# HC32F155 register map
File version: 1.0
CPU: CM0+ r0p1, little endian, no MPU, no FPU, 2 interrupt priority bits
Registers are 32-bit, read-write, reset 0x0 unless marked. A register's access mark holds for its fields unless they carry their own. Offsets are from the block's base; [hi:lo] are bit positions; {n}, {i} and the like mark numbered series.

## I2C
Base 0x40004800
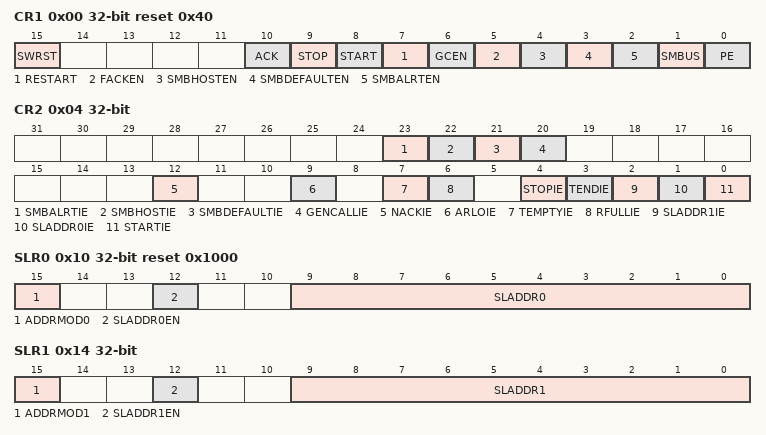
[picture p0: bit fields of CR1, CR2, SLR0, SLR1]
0x00 CR1 reset 0x40
  [15] SWRST, [10] ACK, [9] STOP, [8] START, [7] RESTART, [6] GCEN, [5] FACKEN, [4] SMBHOSTEN, [3] SMBDEFAULTEN, [2] SMBALRTEN, [1] SMBUS, [0] PE
0x04 CR2
  [23] SMBALRTIE, [22] SMBHOSTIE, [21] SMBDEFAULTIE, [20] GENCALLIE, [12] NACKIE, [9] ARLOIE, [7] TEMPTYIE, [6] RFULLIE, [4] STOPIE, [3] TENDIE, [2] SLADDR1IE, [1] SLADDR0IE, [0] STARTIE
0x0C CR4 reset 0x300307
  [10] BUSWAIT
0x10 SLR0 reset 0x1000
  [15] ADDRMOD0, [12] SLADDR0EN, [9:0] SLADDR0
0x14 SLR1
  [15] ADDRMOD1, [12] SLADDR1EN, [9:0] SLADDR1
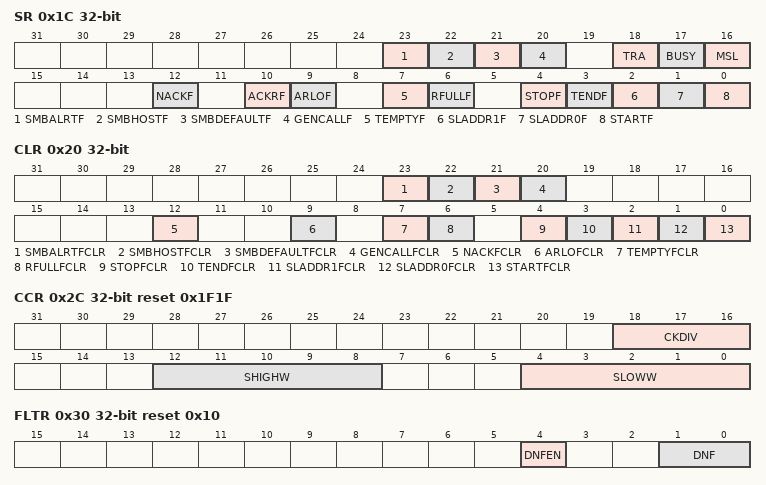
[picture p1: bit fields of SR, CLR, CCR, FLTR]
0x1C SR
  [23] SMBALRTF ro, [22] SMBHOSTF ro, [21] SMBDEFAULTF ro, [20] GENCALLF ro, [18] TRA, [17] BUSY ro, [16] MSL, [12] NACKF ro, [10] ACKRF ro, [9] ARLOF ro, [7] TEMPTYF ro, [6] RFULLF ro, [4] STOPF ro, [3] TENDF ro, [2] SLADDR1F ro, [1] SLADDR0F ro, [0] STARTF ro
0x20 CLR wo
  [23] SMBALRTFCLR, [22] SMBHOSTFCLR, [21] SMBDEFAULTFCLR, [20] GENCALLFCLR, [12] NACKFCLR, [9] ARLOFCLR, [7] TEMPTYFCLR, [6] RFULLFCLR, [4] STOPFCLR, [3] TENDFCLR, [2] SLADDR1FCLR, [1] SLADDR0FCLR, [0] STARTFCLR
0x24 DTR 8-bit reset 0xFF
0x28 DRR 8-bit
0x2C CCR reset 0x1F1F
  [18:16] CKDIV, [12:8] SHIGHW, [4:0] SLOWW
0x30 FLTR reset 0x10
  [4] DNFEN, [1:0] DNF

## ICG
Base 0x000000C0
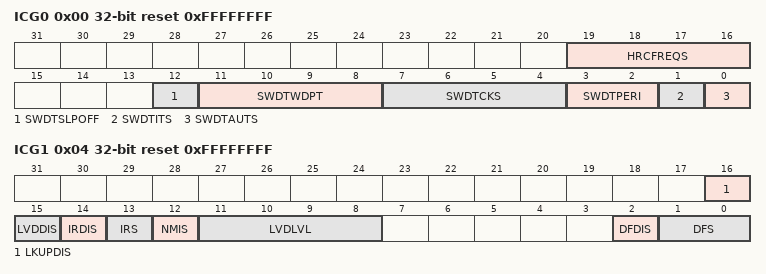
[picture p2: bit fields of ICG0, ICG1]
0x00 ICG0 ro reset 0xFFFFFFFF
  [19:16] HRCFREQS, [12] SWDTSLPOFF, [11:8] SWDTWDPT, [7:4] SWDTCKS, [3:2] SWDTPERI, [1] SWDTITS, [0] SWDTAUTS
0x04 ICG1 ro reset 0xFFFFFFFF
  [16] LKUPDIS, [15] LVDDIS, [14] IRDIS, [13] IRS, [12] NMIS, [11:8] LVDLVL, [2] DFDIS, [1:0] DFS
{0x0+4i} ICG{i} ro reset 0xFFFFFFFF (reset mask 0x0) (i=2..6)

## INTC
Base 0x40011000
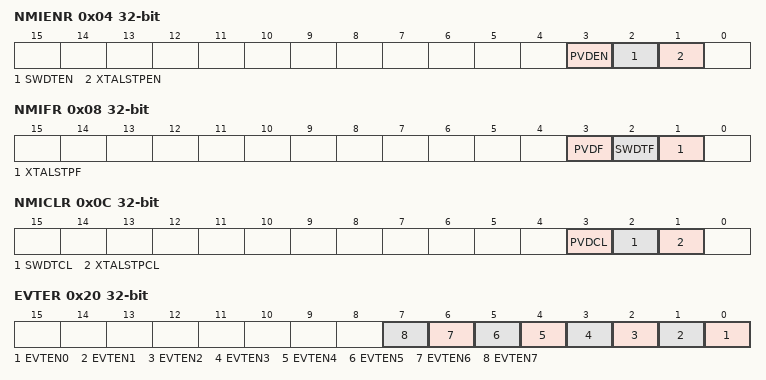
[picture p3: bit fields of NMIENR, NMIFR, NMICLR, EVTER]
0x04 NMIENR
  [3] PVDEN, [2] SWDTEN, [1] XTALSTPEN
0x08 NMIFR ro
  [3] PVDF, [2] SWDTF, [1] XTALSTPF
0x0C NMICLR
  [3] PVDCL, [2] SWDTCL, [1] XTALSTPCL
0x20 EVTER
  [n] EVTEN{n} (n=0..7)
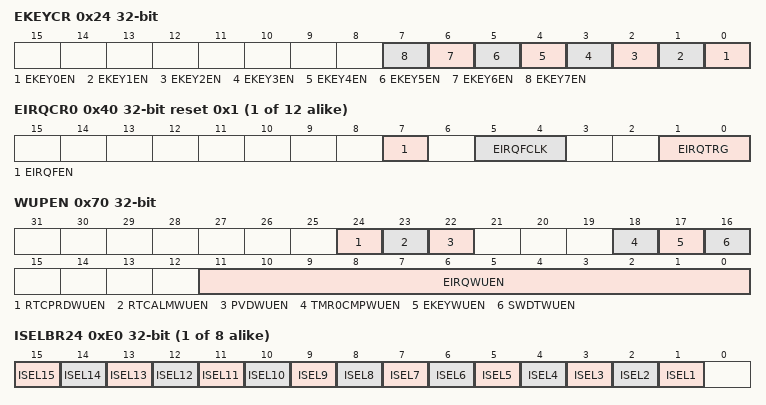
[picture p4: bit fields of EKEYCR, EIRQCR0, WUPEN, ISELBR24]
0x24 EKEYCR
  [n] EKEY{n}EN (n=0..7)
0x3C FPRCR
  [7:0] FPRC
{0x40+4i} EIRQCR{i} reset 0x1 (i=0..11)
  [7] EIRQFEN, [5:4] EIRQFCLK, [1:0] EIRQTRG
0x70 WUPEN
  [24] RTCPRDWUEN, [23] RTCALMWUEN, [22] PVDWUEN, [18] TMR0CMPWUEN, [17] EKEYWUEN, [16] SWDTWUEN, [11:0] EIRQWUEN
0x74 EIRQFR
  [11:0] EIRQF
0x78 EIRQCLR
  [11:0] EIRQCL
{0x80+4i} ISELAR{i} (i=8..23)
  [3:0] ISEL
{0x80+4i} ISELBR{i} (i=24..31)
  [n] ISEL{n} (n=1..15)

## PWC
Base 0x40014000
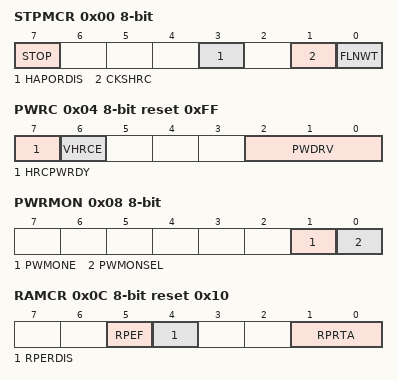
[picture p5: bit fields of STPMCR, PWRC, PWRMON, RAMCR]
0x00 STPMCR 8-bit
  [7] STOP, [3] HAPORDIS, [1] CKSHRC, [0] FLNWT
0x04 PWRC 8-bit reset 0xFF
  [7] HRCPWRDY, [6] VHRCE, [2:0] PWDRV
0x08 PWRMON 8-bit
  [1] PWMONE, [0] PWMONSEL
0x0C RAMCR 8-bit reset 0x10
  [5] RPEF, [4] RPERDIS, [1:0] RPRTA
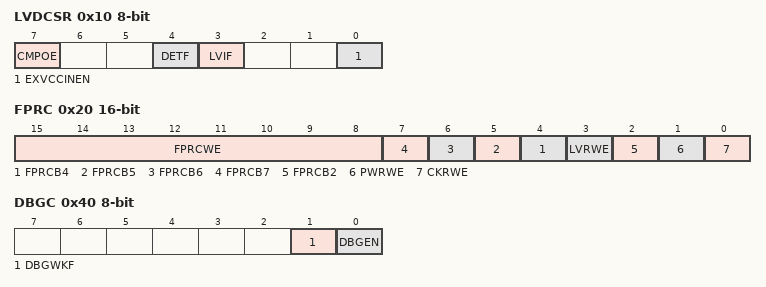
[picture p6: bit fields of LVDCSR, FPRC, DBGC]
0x10 LVDCSR 8-bit
  [7] CMPOE, [4] DETF, [3] LVIF, [0] EXVCCINEN
0x20 FPRC 16-bit
  [15:8] FPRCWE wo, [n] FPRCB{n} (n=4..7), [3] LVRWE, [2] FPRCB2, [1] PWRWE, [0] CKRWE
0x40 DBGC 8-bit
  [1] DBGWKF ro, [0] DBGEN

## RMU
Base 0x40014100
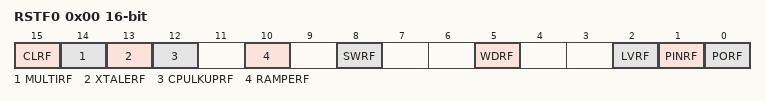
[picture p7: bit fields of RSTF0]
0x00 RSTF0 16-bit
  [15] CLRF, [14] MULTIRF, [13] XTALERF, [12] CPULKUPRF, [10] RAMPERF, [8] SWRF, [5] WDRF, [2] LVRF, [1] PINRF, [0] PORF

## RTC
Base 0x4000D400
0x00 CR0 8-bit
  [0] RESET
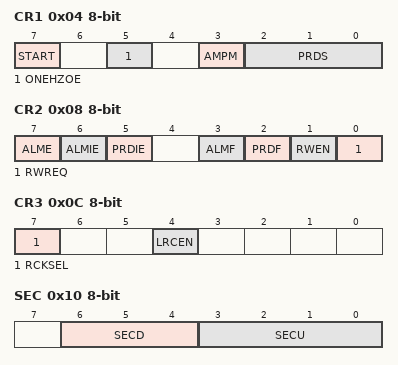
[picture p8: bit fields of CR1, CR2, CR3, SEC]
0x04 CR1 8-bit
  [7] START, [5] ONEHZOE, [3] AMPM, [2:0] PRDS
0x08 CR2 8-bit
  [7] ALME, [6] ALMIE, [5] PRDIE, [3] ALMF, [2] PRDF, [1] RWEN, [0] RWREQ
0x0C CR3 8-bit
  [7] RCKSEL, [4] LRCEN
0x10 SEC 8-bit
  [6:4] SECD, [3:0] SECU
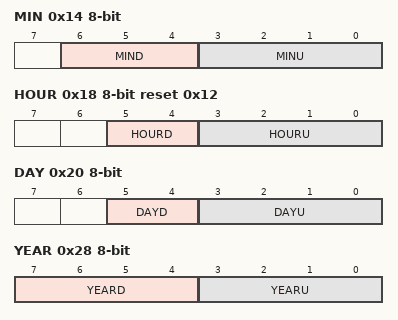
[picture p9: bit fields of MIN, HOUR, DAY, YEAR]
0x14 MIN 8-bit
  [6:4] MIND, [3:0] MINU
0x18 HOUR 8-bit reset 0x12
  [5:4] HOURD, [3:0] HOURU
0x1C WEEK 8-bit
  [2:0] WEEK
0x20 DAY 8-bit
  [5:4] DAYD, [3:0] DAYU
0x24 MON 8-bit
  [4:0] MON
0x28 YEAR 8-bit
  [7:4] YEARD, [3:0] YEARU
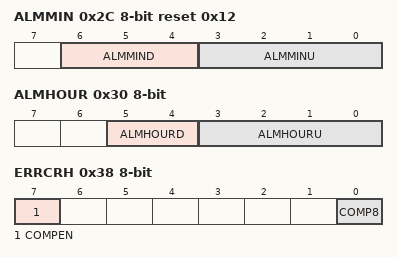
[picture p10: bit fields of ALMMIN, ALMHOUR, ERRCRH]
0x2C ALMMIN 8-bit reset 0x12
  [6:4] ALMMIND, [3:0] ALMMINU
0x30 ALMHOUR 8-bit
  [5:4] ALMHOURD, [3:0] ALMHOURU
0x34 ALMWEEK 8-bit
  [6:0] ALMWEEK
0x38 ERRCRH 8-bit
  [7] COMPEN, [0] COMP8
0x3C ERRCRL 8-bit reset 0x20
  [7:0] COMP

## SPI
Base 0x40003800
0x00 DR
  [15:0] SPD
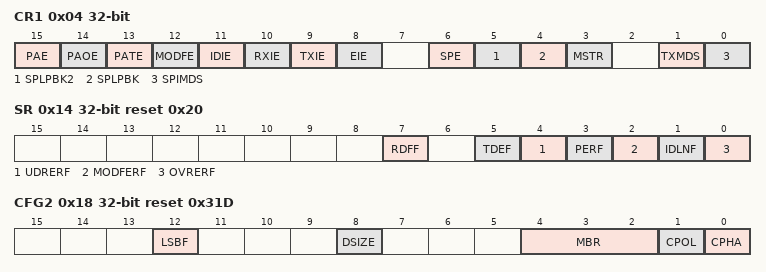
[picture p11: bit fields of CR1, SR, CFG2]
0x04 CR1
  [15] PAE, [14] PAOE, [13] PATE, [12] MODFE, [11] IDIE, [10] RXIE, [9] TXIE, [8] EIE, [6] SPE, [5] SPLPBK2, [4] SPLPBK, [3] MSTR, [1] TXMDS, [0] SPIMDS
0x0C CFG1 reset 0x10
  [8] SS0PV
0x14 SR reset 0x20
  [7] RDFF, [5] TDEF, [4] UDRERF, [3] PERF, [2] MODFERF, [1] IDLNF ro, [0] OVRERF
0x18 CFG2 reset 0x31D
  [12] LSBF, [8] DSIZE, [4:2] MBR, [1] CPOL, [0] CPHA

## SWDT
Base 0x4000CC00
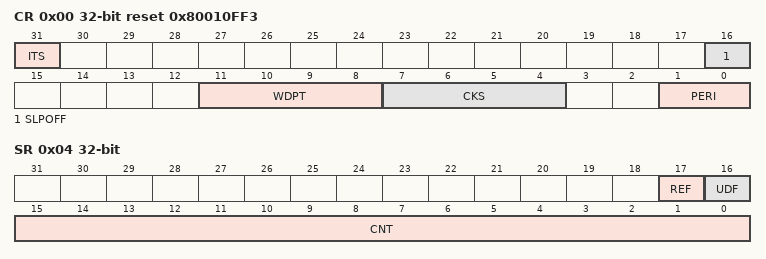
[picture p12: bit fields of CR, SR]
0x00 CR reset 0x80010FF3
  [31] ITS, [16] SLPOFF, [11:8] WDPT, [7:4] CKS, [1:0] PERI
0x04 SR
  [17] REF, [16] UDF, [15:0] CNT ro
0x08 RR
  [15:0] RF

## TMR0
Base 0x40005800
0x00 CNTAR
  [15:0] CNTA
0x08 CMPAR reset 0xFFFF
  [15:0] CMPA
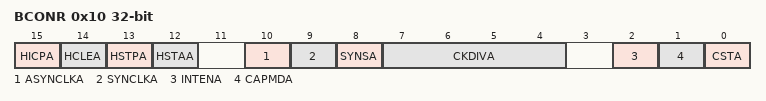
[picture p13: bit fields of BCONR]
0x10 BCONR
  [15] HICPA, [14] HCLEA, [13] HSTPA, [12] HSTAA, [10] ASYNCLKA, [9] SYNCLKA, [8] SYNSA, [7:4] CKDIVA, [2] INTENA, [1] CAPMDA, [0] CSTA
0x14 STFLR
  [0] CMFA

## TMRB1 — desc TMRB
Base 0x40007800
Same registers: TMRB2 0x40007C00, TMRB3 0x40008000, TMRB4 0x40008400, TMRB5 0x40008800, TMRB6 0x40008C00, TMRB7 0x40009000, TMRB8 0x40009400
0x00 CNTER 16-bit
0x04 PERAR 16-bit reset 0xFFFF
0x40 CMPAR 16-bit reset 0xFFFF
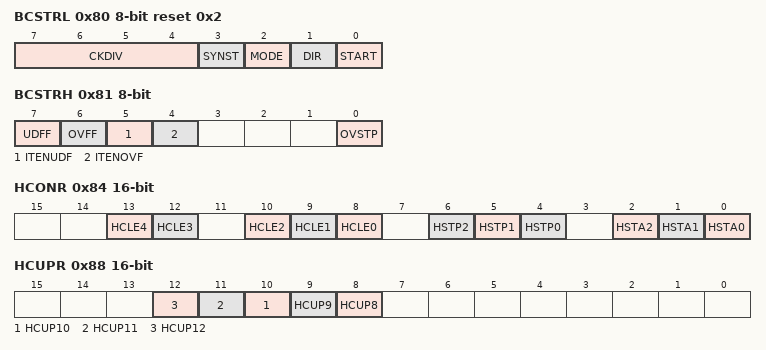
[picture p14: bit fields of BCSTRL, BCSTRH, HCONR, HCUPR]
0x80 BCSTRL 8-bit reset 0x2
  [7:4] CKDIV, [3] SYNST, [2] MODE, [1] DIR, [0] START
0x81 BCSTRH 8-bit
  [7] UDFF, [6] OVFF, [5] ITENUDF, [4] ITENOVF, [0] OVSTP
0x84 HCONR 16-bit
  [13] HCLE4, [12] HCLE3, [10] HCLE2, [9] HCLE1, [8] HCLE0, [6] HSTP2, [5] HSTP1, [4] HSTP0, [2] HSTA2, [1] HSTA1, [0] HSTA0
0x88 HCUPR 16-bit
  [n] HCUP{n} (n=8..12)
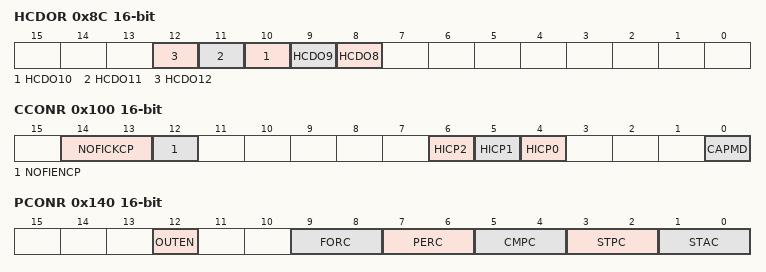
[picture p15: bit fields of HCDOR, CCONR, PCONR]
0x8C HCDOR 16-bit
  [n] HCDO{n} (n=8..12)
0x90 ICONR 16-bit
  [0] ITEN1
0x94 ECONR 16-bit
  [0] ETEN1
0x9C STFLR 16-bit
  [0] CMPF1
0x100 CCONR 16-bit
  [14:13] NOFICKCP, [12] NOFIENCP, [6] HICP2, [5] HICP1, [4] HICP0, [0] CAPMD
0x140 PCONR 16-bit
  [12] OUTEN, [9:8] FORC, [7:6] PERC, [5:4] CMPC, [3:2] STPC, [1:0] STAC

## USART1 — desc USART
Base 0x40001800
Same registers: USART2 0x40001C00, USART3 0x40002000, USART4 0x40002400, USART5 0x40002800, USART6 0x40002C00
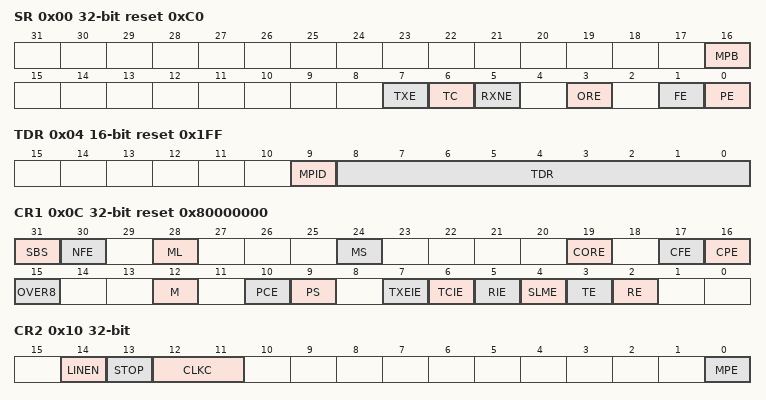
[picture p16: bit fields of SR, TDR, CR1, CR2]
0x00 SR ro reset 0xC0
  [16] MPB, [7] TXE, [6] TC, [5] RXNE, [3] ORE, [1] FE, [0] PE
0x04 TDR 16-bit reset 0x1FF
  [9] MPID, [8:0] TDR
0x06 RDR 16-bit ro
  [8:0] RDR
0x08 BRR reset 0xFF00
  [15:8] DIV_INTEGER
0x0C CR1 reset 0x80000000
  [31] SBS, [30] NFE, [28] ML, [24] MS, [19] CORE wo, [17] CFE wo, [16] CPE wo, [15] OVER8, [12] M, [10] PCE, [9] PS, [7] TXEIE, [6] TCIE, [5] RIE, [4] SLME, [3] TE, [2] RE
0x10 CR2
  [14] LINEN, [13] STOP, [12:11] CLKC, [0] MPE
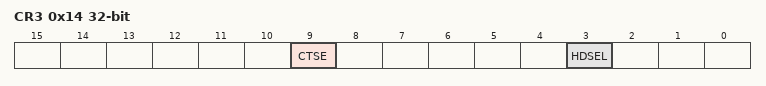
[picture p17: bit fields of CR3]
0x14 CR3
  [9] CTSE, [3] HDSEL
0x18 PR
  [1:0] PSC
